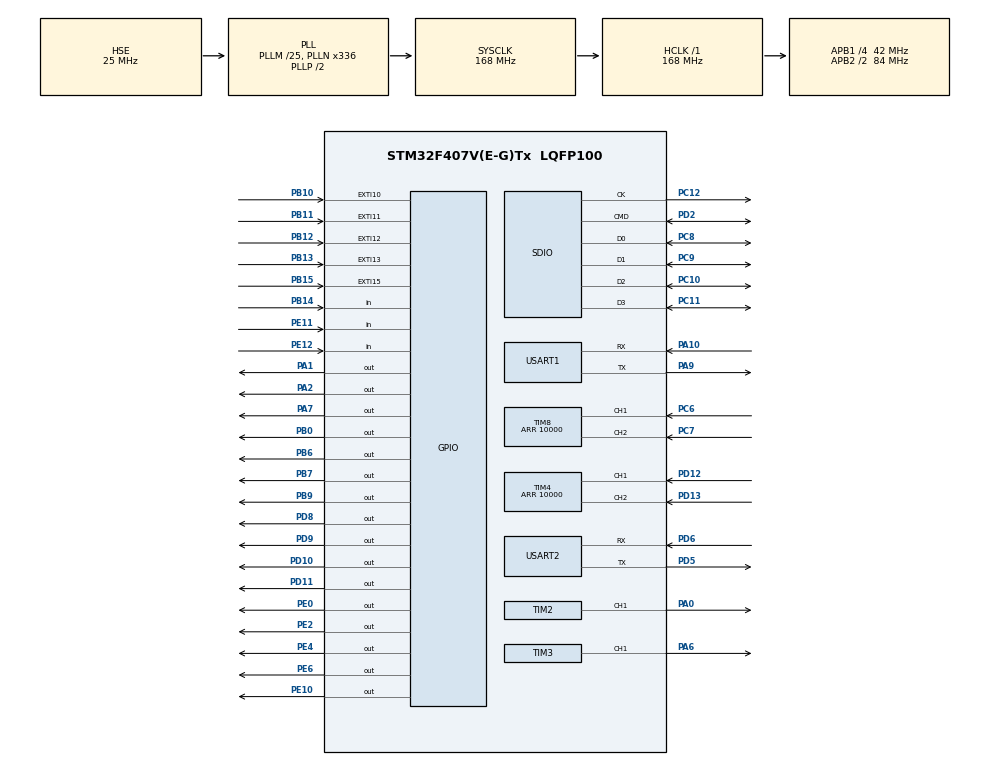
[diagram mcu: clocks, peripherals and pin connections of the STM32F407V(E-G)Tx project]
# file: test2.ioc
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FATFS._USE_BUFF_WO_ALIGNMENT=2
FATFS._USE_ERASE=0
Mcu.Family=STM32F4
Mcu.Name=STM32F407V(E-G)Tx
Mcu.Package=LQFP100
NVIC.EXTI15_10_IRQn=true\:6\:0\:true\:false\:true
NVIC.PriorityGroup=NVIC_PRIORITYGROUP_4
NVIC.SDIO_IRQn=true\:4\:0\:true\:false\:true
NVIC.TIM1_BRK_TIM9_IRQn=true\:3\:0\:true\:false\:true
NVIC.TIM2_IRQn=true\:2\:0\:true\:false\:true
NVIC.TIM3_IRQn=true\:2\:0\:true\:false\:true
NVIC.TIM4_IRQn=true\:2\:0\:true\:false\:true
NVIC.TIM8_BRK_TIM12_IRQn=true\:2\:0\:true\:false\:true
NVIC.USART1_IRQn=true\:2\:0\:true\:false\:true
NVIC.USART2_IRQn=true\:4\:0\:true\:false\:true
PA0-WKUP.Signal=S_TIM2_CH1_ETR
PA1.Signal=GPIO_Output
PA10.Mode=Asynchronous
PA10.Signal=USART1_RX
PA13.Mode=Serial_Wire
PA13.Signal=SYS_JTMS-SWDIO
PA14.Mode=Serial_Wire
PA14.Signal=SYS_JTCK-SWCLK
PA2.PinState=GPIO_PIN_SET
PA2.Signal=GPIO_Output
PA6.Signal=S_TIM3_CH1
PA7.Signal=GPIO_Output
PA9.Mode=Asynchronous
PA9.Signal=USART1_TX
PB0.PinState=GPIO_PIN_SET
PB0.Signal=GPIO_Output
PB10.GPIO_ModeDefaultEXTI=GPIO_MODE_IT_FALLING
PB10.GPIO_PuPd=GPIO_PULLUP
PB10.Signal=GPXTI10
PB11.GPIO_ModeDefaultEXTI=GPIO_MODE_IT_FALLING
PB11.GPIO_PuPd=GPIO_PULLUP
PB11.Signal=GPXTI11
PB12.GPIO_ModeDefaultEXTI=GPIO_MODE_IT_FALLING
PB12.GPIO_PuPd=GPIO_PULLUP
PB12.Signal=GPXTI12
PB13.GPIO_ModeDefaultEXTI=GPIO_MODE_IT_FALLING
PB13.GPIO_PuPd=GPIO_PULLUP
PB13.Signal=GPXTI13
PB14.GPIO_PuPd=GPIO_PULLUP
PB14.Signal=GPIO_Input
PB15.GPIO_ModeDefaultEXTI=GPIO_MODE_IT_FALLING
PB15.GPIO_PuPd=GPIO_PULLUP
PB15.Signal=GPXTI15
PB6.GPIO_ModeDefaultOutputPP=GPIO_MODE_OUTPUT_OD
PB6.Signal=GPIO_Output
PB7.GPIO_ModeDefaultOutputPP=GPIO_MODE_OUTPUT_OD
PB7.Signal=GPIO_Output
PB9.Signal=GPIO_Output
PC10.Mode=SD_4_bits_Wide_bus
PC10.Signal=SDIO_D2
PC11.Mode=SD_4_bits_Wide_bus
PC11.Signal=SDIO_D3
PC12.Mode=SD_4_bits_Wide_bus
PC12.Signal=SDIO_CK
PC6.GPIO_PuPd=GPIO_PULLUP
PC6.Signal=S_TIM8_CH1
PC7.GPIO_PuPd=GPIO_PULLUP
PC7.Signal=S_TIM8_CH2
PC8.Mode=SD_4_bits_Wide_bus
PC8.Signal=SDIO_D0
PC9.Mode=SD_4_bits_Wide_bus
PC9.Signal=SDIO_D1
PD10.Signal=GPIO_Output
PD11.Signal=GPIO_Output
PD12.GPIO_PuPd=GPIO_PULLUP
PD12.Signal=S_TIM4_CH1
PD13.GPIO_PuPd=GPIO_PULLUP
PD13.Signal=S_TIM4_CH2
PD2.Mode=SD_4_bits_Wide_bus
PD2.Signal=SDIO_CMD
PD5.Mode=Asynchronous
PD5.Signal=USART2_TX
PD6.Mode=Asynchronous
PD6.Signal=USART2_RX
PD8.Signal=GPIO_Output
PD9.Signal=GPIO_Output
PE0.GPIO_PuPd=GPIO_PULLUP
PE0.PinState=GPIO_PIN_SET
PE0.Signal=GPIO_Output
PE10.Signal=GPIO_Output
PE11.GPIO_PuPd=GPIO_PULLUP
PE11.Signal=GPIO_Input
PE12.GPIO_PuPd=GPIO_PULLUP
PE12.Signal=GPIO_Input
PE2.GPIO_PuPd=GPIO_PULLUP
PE2.PinState=GPIO_PIN_SET
PE2.Signal=GPIO_Output
PE4.GPIO_PuPd=GPIO_PULLUP
PE4.PinState=GPIO_PIN_SET
PE4.Signal=GPIO_Output
PE6.GPIO_PuPd=GPIO_PULLUP
PE6.PinState=GPIO_PIN_SET
PE6.Signal=GPIO_Output
PH0-OSC_IN.Mode=HSE-External-Oscillator
PH0-OSC_IN.Signal=RCC_OSC_IN
PH1-OSC_OUT.Mode=HSE-External-Oscillator
PH1-OSC_OUT.Signal=RCC_OSC_OUT
ProjectManager.HeapSize=0x200
ProjectManager.StackSize=0x400
ProjectManager.TargetToolchain=EWARM
RCC.48MHZClocksFreq_Value=48000000
RCC.AHBCLKDivider=RCC_SYSCLK_DIV1
RCC.AHBFreq_Value=168000000
RCC.APB1CLKDivider=RCC_HCLK_DIV4
RCC.APB1Freq_Value=42000000
RCC.APB1TimFreq_Value=84000000
RCC.APB2CLKDivider=RCC_HCLK_DIV2
RCC.APB2Freq_Value=84000000
RCC.APB2TimFreq_Value=168000000
RCC.ClockTypeHCLK=RCC_CLOCKTYPE_HCLK
RCC.ClockTypePCLK1=RCC_CLOCKTYPE_PCLK1
RCC.ClockTypePCLK2=RCC_CLOCKTYPE_PCLK2
RCC.ClockTypeSysClk=RCC_CLOCKTYPE_SYSCLK
RCC.CortexFreq_Value=168000000
RCC.Cortex_Div=SYSTICK_CLKSOURCE_HCLK
RCC.EnableExtClockForI2S=false
RCC.EnableHSE=true
RCC.EnableHSERTCDevisor=false
RCC.EnableLSE=false
RCC.EnableLSERTC=false
RCC.ExtClockEnable=false
RCC.HCLKFreq_Value=168000000
RCC.HSEState=RCC_HSE_ON
RCC.HSE_VALUE=25000000
RCC.HSIState=RCC_HSI_OFF
RCC.HSI_VALUE=16000000
RCC.I2SEnable=false
RCC.IWDGEnable=false
RCC.LSE_VALUE=32768
RCC.LSIState=RCC_LSI_OFF
RCC.MCO1OutPutEnable=false
RCC.MCO2OutPutEnable=false
RCC.OscillatorTypeHSE=RCC_OSCILLATORTYPE_HSE
RCC.OscillatorTypeHSI=RCC_OSCILLATORTYPE_HSI
RCC.PLLM=25
RCC.PLLN=336
RCC.PLLP=RCC_PLLP_DIV2
RCC.PLLQ=7
RCC.PLLSource=RCC_PLLSOURCE_HSE
RCC.PLLSourceVirtual=RCC_PLLSOURCE_HSE
RCC.PLLState=RCC_PLL_ON
RCC.RCC_MCODiv1=RCC_MCODIV_1
RCC.RCC_MCODiv2=RCC_MCODIV_1
RCC.RCC_PERIPHCLK_I2SVar=RCC_PERIPHCLK_I2S
RCC.RCC_PERIPHCLK_RTCVar=RCC_PERIPHCLK_RTC
RCC.RCC_RTC_Clock_Source_FROM_HSE=RCC_RTCCLKSOURCE_HSE_DIV2
RCC.RNGEnable=false
RCC.RTCEnable=false
RCC.SDIOEnable=true
RCC.SYSCLKFreq_VALUE=168000000
RCC.SYSCLKSource=RCC_SYSCLKSOURCE_PLLCLK
RCC.USBFSEnable=false
RCC.USBHSEnable=false
RCC.VCOOutputFreq_Value=336000000
SDIO.BusWide=SDIO_BUS_WIDE_1B
SDIO.ClockBypass=SDIO_CLOCK_BYPASS_DISABLE
SDIO.ClockEdge=SDIO_CLOCK_EDGE_RISING
SDIO.ClockPowerSave=SDIO_CLOCK_POWER_SAVE_DISABLE
SDIO.HardwareFlowControl=SDIO_HARDWARE_FLOW_CONTROL_DISABLE
SDIO.WideMode=SDIO_BUS_WIDE_4B
SH.S_TIM2_CH1_ETR.0=TIM2_CH1,PWM Generation1 CH1
SH.S_TIM3_CH1.0=TIM3_CH1,PWM Generation1 CH1
SH.S_TIM4_CH1.0=TIM4_CH1,Encoder_Interface
SH.S_TIM4_CH2.0=TIM4_CH2,Encoder_Interface
SH.S_TIM8_CH1.0=TIM8_CH1,Encoder_Interface
SH.S_TIM8_CH2.0=TIM8_CH2,Encoder_Interface
TIM2.Channel-PWM\ Generation1\ CH1=TIM_CHANNEL_1
TIM2.OCMode_PWM-PWM\ Generation1\ CH1=TIM_OCMODE_PWM1
TIM2.Period=100-1
TIM2.Prescaler=84-1
TIM3.Channel-PWM\ Generation1\ CH1=TIM_CHANNEL_1
TIM3.Period=100-1
TIM3.Prescaler=84-1
TIM4.EncoderMode=TIM_ENCODERMODE_TI12
TIM4.Period=10000
TIM8.EncoderMode=TIM_ENCODERMODE_TI12
TIM8.Period=10000
TIM9.Period=10000-1
TIM9.Prescaler=168-1
USART1.HwFlowCtl-Asynchronous=UART_HWCONTROL_NONE
USART1.VirtualMode=VM_ASYNC
USART2.HwFlowCtl-Asynchronous=UART_HWCONTROL_NONE
USART2.VirtualMode=VM_ASYNC
VP_FATFS_VS_SDIO.Mode=SDIO
VP_TIM2_VS_ClockSourceINT.Mode=Internal
VP_TIM3_VS_ClockSourceINT.Mode=Internal
VP_TIM9_VS_ClockSourceINT.Mode=Internal
board=test2

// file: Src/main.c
/**
  ******************************************************************************
  * File Name          : main.c
  * Description        : Main program body
  ******************************************************************************
  *
  * Copyright (c) 2017 STMicroelectronics International N.V.
  * All rights reserved.
  *
  * Redistribution and use in source and binary forms, with or without
  * modification, are permitted, provided that the following conditions are met:
  *
  * 1. Redistribution of source code must retain the above copyright notice,
  *    this list of conditions and the following disclaimer.
  * 2. Redistributions in binary form must reproduce the above copyright notice,
  *    this list of conditions and the following disclaimer in the documentation
  *    and/or other materials provided with the distribution.
  * 3. Neither the name of STMicroelectronics nor the names of other
  *    contributors to this software may be used to endorse or promote products
  *    derived from this software without specific written permission.
  * 4. This software, including modifications and/or derivative works of this
  *    software, must execute solely and exclusively on microcontroller or
  *    microprocessor devices manufactured by or for STMicroelectronics.
  * 5. Redistribution and use of this software other than as permitted under
  *    this license is void and will automatically terminate your rights under
  *    this license.
  *
  * THIS SOFTWARE IS PROVIDED BY STMICROELECTRONICS AND CONTRIBUTORS "AS IS"
  * AND ANY EXPRESS, IMPLIED OR STATUTORY WARRANTIES, INCLUDING, BUT NOT
  * LIMITED TO, THE IMPLIED WARRANTIES OF MERCHANTABILITY, FITNESS FOR A
  * PARTICULAR PURPOSE AND NON-INFRINGEMENT OF THIRD PARTY INTELLECTUAL PROPERTY
  * RIGHTS ARE DISCLAIMED TO THE FULLEST EXTENT PERMITTED BY LAW. IN NO EVENT
  * SHALL STMICROELECTRONICS OR CONTRIBUTORS BE LIABLE FOR ANY DIRECT, INDIRECT,
  * INCIDENTAL, SPECIAL, EXEMPLARY, OR CONSEQUENTIAL DAMAGES (INCLUDING, BUT NOT
  * LIMITED TO, PROCUREMENT OF SUBSTITUTE GOODS OR SERVICES; LOSS OF USE, DATA,
  * OR PROFITS; OR BUSINESS INTERRUPTION) HOWEVER CAUSED AND ON ANY THEORY OF
  * LIABILITY, WHETHER IN CONTRACT, STRICT LIABILITY, OR TORT (INCLUDING
  * NEGLIGENCE OR OTHERWISE) ARISING IN ANY WAY OUT OF THE USE OF THIS SOFTWARE,
  * EVEN IF ADVISED OF THE POSSIBILITY OF SUCH DAMAGE.
  *
  ******************************************************************************
  */
#include "main.h"
#include "stm32f4xx_hal.h"
#include "fatfs.h"
#include "sdio.h"
#include "tim.h"
#include "usart.h"
#include "gpio.h"

/* USER CODE BEGIN Includes */
#include "userinc.h"
#include "init.h"
#include "interrupt.h"
#include "arm_math.h"
#include "stm32f4xx_hal_flash.h"
#include "OLEDUI.h"
#include "data.h"
/* USER CODE END Includes */

/* USER CODE BEGIN PV */
/* Private variables ---------------------------------------------------------*/

/* USER CODE END PV */

void SystemClock_Config(void);
void Error_Handler(void);

/* USER CODE BEGIN PFP */
/* Private function prototypes -----------------------------------------------*/

/* USER CODE END PFP */

int main(void)
{

  /* MCU Configuration----------------------------------------------------------*/

  /* Reset of all peripherals, Initializes the Flash interface and the Systick. */
  HAL_Init();

  /* Configure the system clock */
  SystemClock_Config();

  /* Initialize all configured peripherals */
  MX_GPIO_Init();
  MX_TIM2_Init();
  MX_TIM3_Init();
  MX_TIM4_Init();
  MX_TIM9_Init();
  MX_TIM8_Init();
  MX_SDIO_SD_Init();
  MX_FATFS_Init();
  MX_USART1_UART_Init();
  MX_USART2_UART_Init();

  /* USER CODE BEGIN 2 */

  InitAll();
  /* USER CODE END 2 */

  /* Infinite loop */
  while (1)
  {

  /* USER CODE BEGIN 3 */
    OledShow();
    CheckKey();
    LiveDebug();
  }
  /* USER CODE END 3 */

}

/** System Clock Configuration
*/
void SystemClock_Config(void)
{

  RCC_OscInitTypeDef RCC_OscInitStruct;
  RCC_ClkInitTypeDef RCC_ClkInitStruct;

    /**Configure the main internal regulator output voltage
    */
  __HAL_RCC_PWR_CLK_ENABLE();

  __HAL_PWR_VOLTAGESCALING_CONFIG(PWR_REGULATOR_VOLTAGE_SCALE1);

    /**Initializes the CPU, AHB and APB busses clocks
    */
  RCC_OscInitStruct.OscillatorType =RCC_OSCILLATORTYPE_HSE;
  RCC_OscInitStruct.HSEState = RCC_HSE_ON;
  RCC_OscInitStruct.PLL.PLLState = RCC_PLL_ON;
  RCC_OscInitStruct.PLL.PLLSource = RCC_PLLSOURCE_HSE;
  RCC_OscInitStruct.PLL.PLLM = 25;
  RCC_OscInitStruct.PLL.PLLN = 336;
  RCC_OscInitStruct.PLL.PLLP = RCC_PLLP_DIV2;
  RCC_OscInitStruct.PLL.PLLQ = 7;
  if (HAL_RCC_OscConfig(&RCC_OscInitStruct) != HAL_OK)
  {
    Error_Handler();
  }

    /**Initializes the CPU, AHB and APB busses clocks
    */
  RCC_ClkInitStruct.ClockType = RCC_CLOCKTYPE_HCLK|RCC_CLOCKTYPE_SYSCLK
                              |RCC_CLOCKTYPE_PCLK1|RCC_CLOCKTYPE_PCLK2;
  RCC_ClkInitStruct.SYSCLKSource = RCC_SYSCLKSOURCE_PLLCLK;
  RCC_ClkInitStruct.AHBCLKDivider = RCC_SYSCLK_DIV1;
  RCC_ClkInitStruct.APB1CLKDivider = RCC_HCLK_DIV4;
  RCC_ClkInitStruct.APB2CLKDivider = RCC_HCLK_DIV2;

  if (HAL_RCC_ClockConfig(&RCC_ClkInitStruct, FLASH_LATENCY_5) != HAL_OK)
  {
    Error_Handler();
  }

    /**Configure the Systick interrupt time
    */
  HAL_SYSTICK_Config(HAL_RCC_GetHCLKFreq()/1000);

    /**Configure the Systick
    */
  HAL_SYSTICK_CLKSourceConfig(SYSTICK_CLKSOURCE_HCLK);

  /* SysTick_IRQn interrupt configuration */
  HAL_NVIC_SetPriority(SysTick_IRQn, 0, 0);
}

void Error_Handler(void)
{
  while(1)
  {
  }
}

/************************ (C) COPYRIGHT STMicroelectronics *****END OF FILE****/
